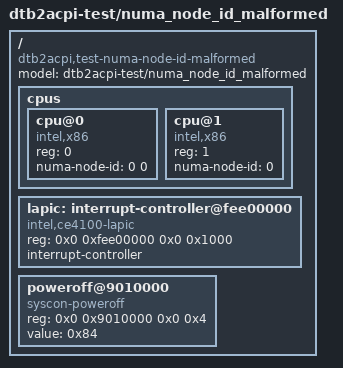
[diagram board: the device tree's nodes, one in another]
/dts-v1/;

/* `numa-node-id` on a cpu node is malformed: 8 bytes (two cells)
 * instead of a single u32. `DtbNode::property_u32_opt` calls
 * `as_u32()` and surfaces `MalformedProperty { site: Cpus,
 * property: "numa-node-id" }` from inside `walk_cpus`'s
 * `child.property_u32_opt("numa-node-id")?` call. (Site is the
 * children-iter's parent site — `Cpus`.)
 */

/ {
	#address-cells = <2>;
	#size-cells = <2>;
	model = "dtb2acpi-test/numa_node_id_malformed";
	compatible = "dtb2acpi,test-numa-node-id-malformed";

	cpus {
		#address-cells = <1>;
		#size-cells = <0>;

		cpu@0 {
			device_type = "cpu";
			reg = <0>;
			compatible = "intel,x86";
			numa-node-id = <0 0>;
		};

		cpu@1 {
			device_type = "cpu";
			reg = <1>;
			compatible = "intel,x86";
			numa-node-id = <0>;
		};
	};

		lapic: interrupt-controller@fee00000 {
		compatible = "intel,ce4100-lapic";
		reg = <0x0 0xfee00000 0x0 0x1000>;
		interrupt-controller;
		#interrupt-cells = <2>;
	};
		poweroff@9010000 {
		compatible = "syscon-poweroff";
		reg = <0x0 0x9010000 0x0 0x4>;
		value = <0x84>;
	};
};
